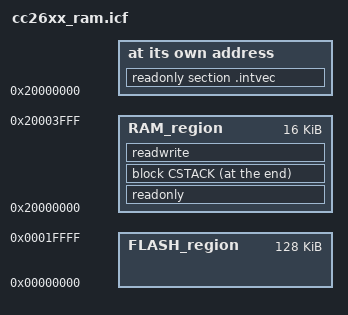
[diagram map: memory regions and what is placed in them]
//*****************************************************************************
//! @file       cc26xx_ram.icf
//! @brief      CC26xx linker configuration file for IAR EWARM placing
//!             all sections in device SRAM.
//!
//! Revised     $Date: 2014-03-13 15:21:38 +0100 (to, 13 mar 2014) $
//! Revision    $Revision: 12386 $
//
//  Copyright (C) 2013 Texas Instruments Incorporated - http://www.ti.com/
//
//
//  Redistribution and use in source and binary forms, with or without
//  modification, are permitted provided that the following conditions
//  are met:
//
//    Redistributions of source code must retain the above copyright
//    notice, this list of conditions and the following disclaimer.
//
//    Redistributions in binary form must reproduce the above copyright
//    notice, this list of conditions and the following disclaimer in the
//    documentation and/or other materials provided with the distribution.
//
//    Neither the name of Texas Instruments Incorporated nor the names of
//    its contributors may be used to endorse or promote products derived
//    from this software without specific prior written permission.
//
//  THIS SOFTWARE IS PROVIDED BY THE COPYRIGHT HOLDERS AND CONTRIBUTORS
//  "AS IS" AND ANY EXPRESS OR IMPLIED WARRANTIES, INCLUDING, BUT NOT
//  LIMITED TO, THE IMPLIED WARRANTIES OF MERCHANTABILITY AND FITNESS FOR
//  A PARTICULAR PURPOSE ARE DISCLAIMED. IN NO EVENT SHALL THE COPYRIGHT
//  OWNER OR CONTRIBUTORS BE LIABLE FOR ANY DIRECT, INDIRECT, INCIDENTAL,
//  SPECIAL, EXEMPLARY, OR CONSEQUENTIAL DAMAGES (INCLUDING, BUT NOT
//  LIMITED TO, PROCUREMENT OF SUBSTITUTE GOODS OR SERVICES; LOSS OF USE,
//  DATA, OR PROFITS; OR BUSINESS INTERRUPTION) HOWEVER CAUSED AND ON ANY
//  THEORY OF LIABILITY, WHETHER IN CONTRACT, STRICT LIABILITY, OR TORT
//  (INCLUDING NEGLIGENCE OR OTHERWISE) ARISING IN ANY WAY OUT OF THE USE
//  OF THIS SOFTWARE, EVEN IF ADVISED OF THE POSSIBILITY OF SUCH DAMAGE.
//****************************************************************************/


/*###CC26xx### DO NOT MODIFY USING ICFEDITOR IN IAR IDE! */
/*-Specials-*/
define symbol __intvec_start__ = 0x20000000;
/*-Memory Regions-*/
define symbol __region_FLASH_start__ = 0x00000000;
define symbol __region_FLASH_end__   = 0x0001FFFF;
define symbol __region_RAM_start__ = 0x20000000;
define symbol __region_RAM_end__   = 0x20003FFF;
/*-Sizes-*/
define symbol __size_cstack__ = 0x400;

define memory mem with size = 4G;

define region FLASH_region   = mem:[from __region_FLASH_start__   to __region_FLASH_end__];
define region RAM_region     = mem:[from __region_RAM_start__     to __region_RAM_end__];

//
// Define a region for Customer Configuration Area in flash.
//
// 0x0001F000 + 0x00000FD8
//define region FLASH_CCA = mem:[from 0x0001FFD8 to 0x0001FFFF];

initialize by copy { readwrite };
do not initialize  { section .noinit };


place at address mem: __intvec_start__ { readonly section .intvec };
keep { section .intvec};

//
// Place the cca area at the end of flash (start of FLASH_CCA).
//
//place at start of FLASH_CCA { readonly section .flashcca };

//
// Place remaining 'read only' in Flash
//
//place in FLASH_region { readonly };
place in RAM_region { readonly };


//
// Define CSTACK block to contain .stack section. This enables the IAR IDE
// to properly show the stack content during debug. Place stack at end of
// retention RAM, do not initialize (initializing the stack will destroy the
// return address from the initialization code, causing the processor to branch
// to zero and fault)
//
define block CSTACK with alignment = 8, size = __size_cstack__ { section .stack };
do not initialize { section .stack };
place at end of RAM_region { block CSTACK };

place in RAM_region   { readwrite };

//
// Export stack top symbol. Used by startup file.
//
define exported symbol STACK_TOP = __region_RAM_end__ + 1;
